# ESP32S31_RADIO register map
Vendor: Espressif; Series: ESP32-S31; File version: 3.52
Registers are 32-bit, read-write, no defined reset value unless marked. A register's access mark holds for its fields unless they carry their own. Offsets are from the block's base; [hi:lo] are bit positions.

## MODEM_SYSCON_RADIO — Route-owned MODEM_SYSCON clocks, resets and shared Wi-Fi-baseband control used by the exclusive Wi-Fi, Bluetooth and IEEE 802.15.4 lifecycles.
Base 0x20109C00
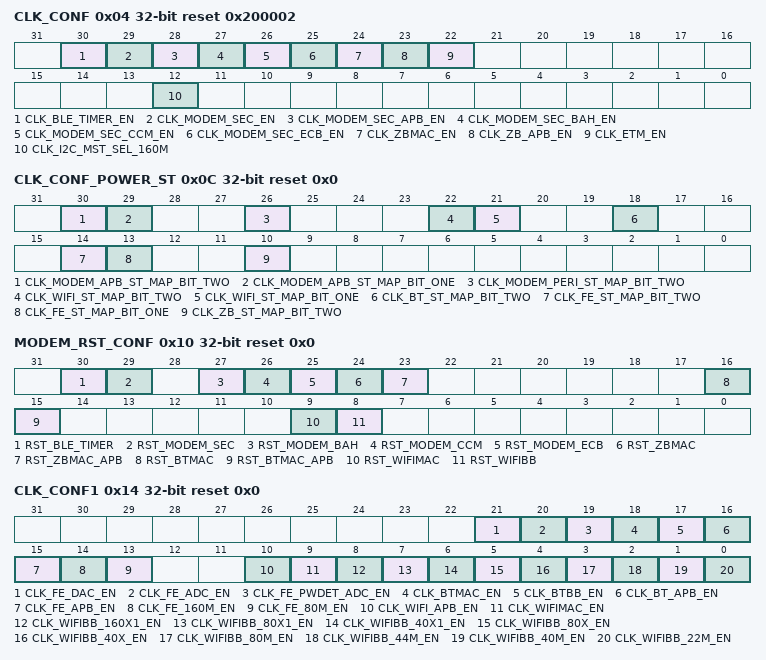
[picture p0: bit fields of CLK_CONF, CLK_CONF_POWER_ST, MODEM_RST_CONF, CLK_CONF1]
0x04 CLK_CONF reset 0x200002 — Shared modem clock selectors and protocol clock gates.
  [30] CLK_BLE_TIMER_EN — Enable the Bluetooth low-power timer clock.
  [29] CLK_MODEM_SEC_EN — Enable the modem-security functional clock.
  [28] CLK_MODEM_SEC_APB_EN — Enable the modem-security APB clock.
  [27] CLK_MODEM_SEC_BAH_EN — Enable the modem-security BAH clock.
  [26] CLK_MODEM_SEC_CCM_EN — Enable the modem-security CCM clock.
  [25] CLK_MODEM_SEC_ECB_EN — Enable the modem-security ECB clock.
  [24] CLK_ZBMAC_EN — Enable the IEEE 802.15.4 MAC clock.
  [23] CLK_ZB_APB_EN — Enable the IEEE 802.15.4 APB clock.
  [22] CLK_ETM_EN — Enable the modem ETM clock.
  [12] CLK_I2C_MST_SEL_160M — Select the 160 MHz PHY-I2C-master source.
0x0C CLK_CONF_POWER_ST reset 0x0 — Six modem-domain power-state clock-map fields.
  [30] CLK_MODEM_APB_ST_MAP_BIT_TWO — Project-assigned name. Bit two of the modem-APB domain state map, set by the reviewed modem clock initialization.
  [29] CLK_MODEM_APB_ST_MAP_BIT_ONE — Project-assigned name. Bit one of the modem-APB domain state map, set by the reviewed modem clock initialization.
  [26] CLK_MODEM_PERI_ST_MAP_BIT_TWO — Project-assigned name. Bit two of the modem-peripheral domain state map, set by the reviewed modem clock initialization.
  [22] CLK_WIFI_ST_MAP_BIT_TWO — Project-assigned name. Bit two of the Wi-Fi domain state map, set by the reviewed modem clock initialization.
  [21] CLK_WIFI_ST_MAP_BIT_ONE — Project-assigned name. Bit one of the Wi-Fi domain state map, set by the reviewed modem clock initialization.
  [18] CLK_BT_ST_MAP_BIT_TWO — Project-assigned name. Bit two of the Bluetooth domain state map, set by the reviewed modem clock initialization.
  [14] CLK_FE_ST_MAP_BIT_TWO — Project-assigned name. Bit two of the radio-front-end domain state map, set by the reviewed modem clock initialization.
  [13] CLK_FE_ST_MAP_BIT_ONE — Project-assigned name. Bit one of the radio-front-end domain state map, set by the reviewed modem clock initialization.
  [10] CLK_ZB_ST_MAP_BIT_TWO — Project-assigned name. Bit two of the IEEE 802.15.4 domain state map, set by the reviewed modem clock initialization.
0x10 MODEM_RST_CONF reset 0x0 — Shared radio-domain reset controls.
  [30] RST_BLE_TIMER — Bluetooth low-power timer reset.
  [29] RST_MODEM_SEC — Modem-security reset.
  [27] RST_MODEM_BAH — Modem-security BAH reset.
  [26] RST_MODEM_CCM — Modem-security CCM reset.
  [25] RST_MODEM_ECB — Modem-security ECB reset.
  [24] RST_ZBMAC — IEEE 802.15.4 MAC reset.
  [23] RST_ZBMAC_APB — IEEE 802.15.4 MAC APB reset.
  [16] RST_BTMAC — Bluetooth MAC reset.
  [15] RST_BTMAC_APB — Bluetooth MAC APB reset.
  [9] RST_WIFIMAC — Wi-Fi MAC reset.
  [8] RST_WIFIBB — Wi-Fi baseband reset.
0x14 CLK_CONF1 reset 0x0 — Wi-Fi, Bluetooth and front-end clock gates.
  [21] CLK_FE_DAC_EN, [20] CLK_FE_ADC_EN, [19] CLK_FE_PWDET_ADC_EN, [18] CLK_BTMAC_EN, [17] CLK_BTBB_EN, [16] CLK_BT_APB_EN, [15] CLK_FE_APB_EN, [14] CLK_FE_160M_EN, [13] CLK_FE_80M_EN, [10] CLK_WIFI_APB_EN, [9] CLK_WIFIMAC_EN, [8] CLK_WIFIBB_160X1_EN, [7] CLK_WIFIBB_80X1_EN, [6] CLK_WIFIBB_40X1_EN, [5] CLK_WIFIBB_80X_EN, [4] CLK_WIFIBB_40X_EN, [3] CLK_WIFIBB_80M_EN, [2] CLK_WIFIBB_44M_EN, [1] CLK_WIFIBB_40M_EN, [0] CLK_WIFIBB_22M_EN
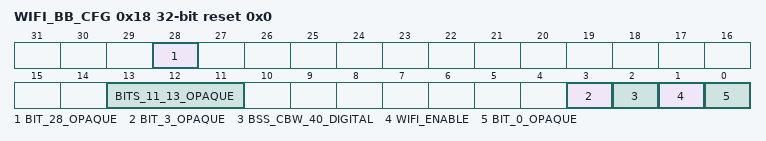
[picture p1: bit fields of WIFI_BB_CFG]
0x18 WIFI_BB_CFG reset 0x0 — Instruction-reviewed Wi-Fi baseband shared control.
  [28] BIT_28_OPAQUE — Opaque: meaning not established.
  [13:11] BITS_11_13_OPAQUE — Opaque: meaning not established. Reviewed baseband AGC update mode used by initialization and subsequent register updates.
    on write: 1=INITIALIZATION; 7=REGISTER_UPDATES_ENABLED
  [3] BIT_3_OPAQUE — Opaque: meaning not established. Cleared by complete phy_bb_bss_cbw40_dig together with BSS_CBW_40_DIGITAL.
  [2] BSS_CBW_40_DIGITAL — Project-assigned name. Digital BSS 40 MHz channel-width control that complete phy_bb_bss_cbw40_dig publishes; zero disables and one enables the recovered path.
    on write: 0=DISABLED; 1=ENABLED
  [1] WIFI_ENABLE
  [0] BIT_0_OPAQUE — Opaque: meaning not established.
